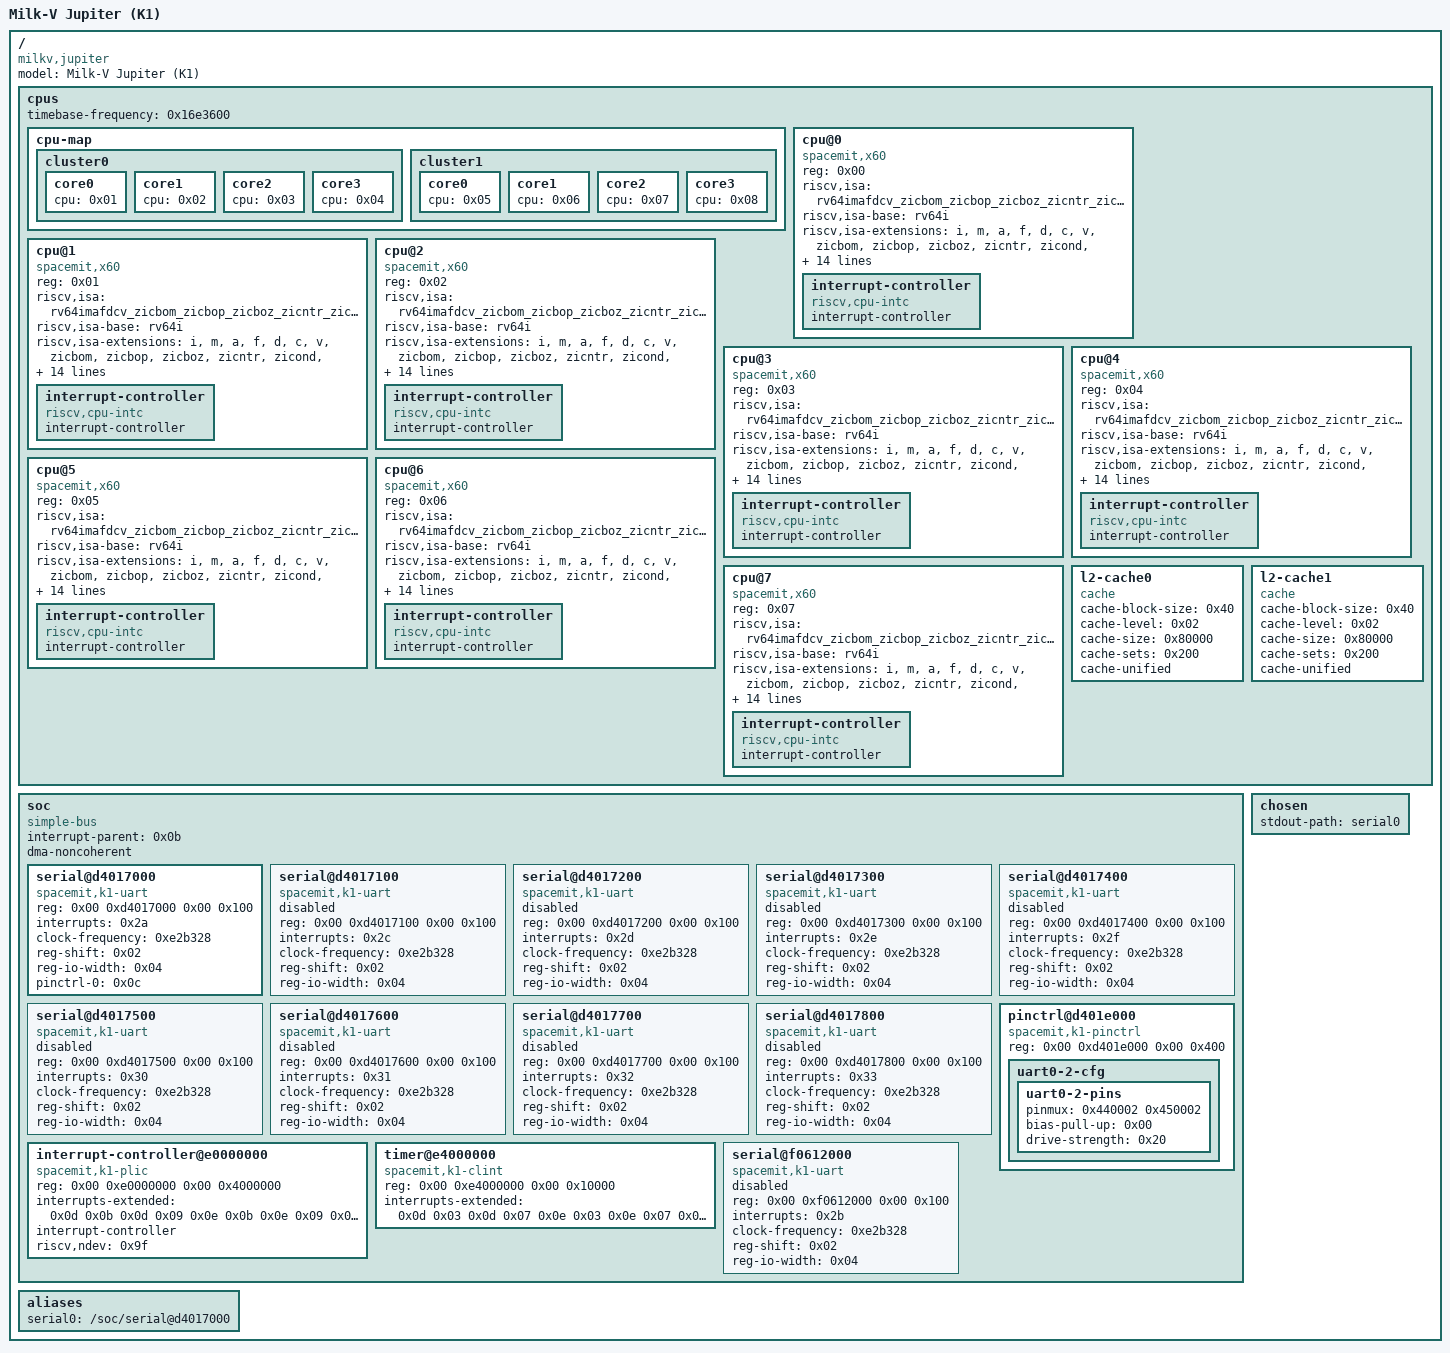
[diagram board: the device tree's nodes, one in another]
/dts-v1/;

/ {
	#address-cells = <0x02>;
	#size-cells = <0x02>;
	model = "Milk-V Jupiter (K1)";
	compatible = "milkv,jupiter", "spacemit,k1";

	cpus {
		#address-cells = <0x01>;
		#size-cells = <0x00>;
		timebase-frequency = <0x16e3600>;

		cpu-map {

			cluster0 {

				core0 {
					cpu = <0x01>;
				};

				core1 {
					cpu = <0x02>;
				};

				core2 {
					cpu = <0x03>;
				};

				core3 {
					cpu = <0x04>;
				};
			};

			cluster1 {

				core0 {
					cpu = <0x05>;
				};

				core1 {
					cpu = <0x06>;
				};

				core2 {
					cpu = <0x07>;
				};

				core3 {
					cpu = <0x08>;
				};
			};
		};

		cpu@0 {
			compatible = "spacemit,x60", "riscv";
			device_type = "cpu";
			reg = <0x00>;
			riscv,isa = "rv64imafdcv_zicbom_zicbop_zicboz_zicntr_zicond_zicsr_zifencei_zihintpause_zihpm_zfh_zba_zbb_zbc_zbs_zkt_zvfh_zvkt_sscofpmf_sstc_svinval_svnapot_svpbmt";
			riscv,isa-base = "rv64i";
			riscv,isa-extensions = "i", "m", "a", "f", "d", "c", "v", "zicbom", "zicbop", "zicboz", "zicntr", "zicond", "zicsr", "zifencei", "zihintpause", "zihpm", "zfh", "zba", "zbb", "zbc", "zbs", "zkt", "zvfh", "zvkt", "sscofpmf", "sstc", "svinval", "svnapot", "svpbmt";
			riscv,cbom-block-size = <0x40>;
			riscv,cbop-block-size = <0x40>;
			riscv,cboz-block-size = <0x40>;
			i-cache-block-size = <0x40>;
			i-cache-size = <0x8000>;
			i-cache-sets = <0x80>;
			d-cache-block-size = <0x40>;
			d-cache-size = <0x8000>;
			d-cache-sets = <0x80>;
			next-level-cache = <0x09>;
			mmu-type = "riscv,sv39";
			phandle = <0x01>;

			interrupt-controller {
				compatible = "riscv,cpu-intc";
				interrupt-controller;
				#interrupt-cells = <0x01>;
				phandle = <0x0d>;
			};
		};

		cpu@1 {
			compatible = "spacemit,x60", "riscv";
			device_type = "cpu";
			reg = <0x01>;
			riscv,isa = "rv64imafdcv_zicbom_zicbop_zicboz_zicntr_zicond_zicsr_zifencei_zihintpause_zihpm_zfh_zba_zbb_zbc_zbs_zkt_zvfh_zvkt_sscofpmf_sstc_svinval_svnapot_svpbmt";
			riscv,isa-base = "rv64i";
			riscv,isa-extensions = "i", "m", "a", "f", "d", "c", "v", "zicbom", "zicbop", "zicboz", "zicntr", "zicond", "zicsr", "zifencei", "zihintpause", "zihpm", "zfh", "zba", "zbb", "zbc", "zbs", "zkt", "zvfh", "zvkt", "sscofpmf", "sstc", "svinval", "svnapot", "svpbmt";
			riscv,cbom-block-size = <0x40>;
			riscv,cbop-block-size = <0x40>;
			riscv,cboz-block-size = <0x40>;
			i-cache-block-size = <0x40>;
			i-cache-size = <0x8000>;
			i-cache-sets = <0x80>;
			d-cache-block-size = <0x40>;
			d-cache-size = <0x8000>;
			d-cache-sets = <0x80>;
			next-level-cache = <0x09>;
			mmu-type = "riscv,sv39";
			phandle = <0x02>;

			interrupt-controller {
				compatible = "riscv,cpu-intc";
				interrupt-controller;
				#interrupt-cells = <0x01>;
				phandle = <0x0e>;
			};
		};

		cpu@2 {
			compatible = "spacemit,x60", "riscv";
			device_type = "cpu";
			reg = <0x02>;
			riscv,isa = "rv64imafdcv_zicbom_zicbop_zicboz_zicntr_zicond_zicsr_zifencei_zihintpause_zihpm_zfh_zba_zbb_zbc_zbs_zkt_zvfh_zvkt_sscofpmf_sstc_svinval_svnapot_svpbmt";
			riscv,isa-base = "rv64i";
			riscv,isa-extensions = "i", "m", "a", "f", "d", "c", "v", "zicbom", "zicbop", "zicboz", "zicntr", "zicond", "zicsr", "zifencei", "zihintpause", "zihpm", "zfh", "zba", "zbb", "zbc", "zbs", "zkt", "zvfh", "zvkt", "sscofpmf", "sstc", "svinval", "svnapot", "svpbmt";
			riscv,cbom-block-size = <0x40>;
			riscv,cbop-block-size = <0x40>;
			riscv,cboz-block-size = <0x40>;
			i-cache-block-size = <0x40>;
			i-cache-size = <0x8000>;
			i-cache-sets = <0x80>;
			d-cache-block-size = <0x40>;
			d-cache-size = <0x8000>;
			d-cache-sets = <0x80>;
			next-level-cache = <0x09>;
			mmu-type = "riscv,sv39";
			phandle = <0x03>;

			interrupt-controller {
				compatible = "riscv,cpu-intc";
				interrupt-controller;
				#interrupt-cells = <0x01>;
				phandle = <0x0f>;
			};
		};

		cpu@3 {
			compatible = "spacemit,x60", "riscv";
			device_type = "cpu";
			reg = <0x03>;
			riscv,isa = "rv64imafdcv_zicbom_zicbop_zicboz_zicntr_zicond_zicsr_zifencei_zihintpause_zihpm_zfh_zba_zbb_zbc_zbs_zkt_zvfh_zvkt_sscofpmf_sstc_svinval_svnapot_svpbmt";
			riscv,isa-base = "rv64i";
			riscv,isa-extensions = "i", "m", "a", "f", "d", "c", "v", "zicbom", "zicbop", "zicboz", "zicntr", "zicond", "zicsr", "zifencei", "zihintpause", "zihpm", "zfh", "zba", "zbb", "zbc", "zbs", "zkt", "zvfh", "zvkt", "sscofpmf", "sstc", "svinval", "svnapot", "svpbmt";
			riscv,cbom-block-size = <0x40>;
			riscv,cbop-block-size = <0x40>;
			riscv,cboz-block-size = <0x40>;
			i-cache-block-size = <0x40>;
			i-cache-size = <0x8000>;
			i-cache-sets = <0x80>;
			d-cache-block-size = <0x40>;
			d-cache-size = <0x8000>;
			d-cache-sets = <0x80>;
			next-level-cache = <0x09>;
			mmu-type = "riscv,sv39";
			phandle = <0x04>;

			interrupt-controller {
				compatible = "riscv,cpu-intc";
				interrupt-controller;
				#interrupt-cells = <0x01>;
				phandle = <0x10>;
			};
		};

		cpu@4 {
			compatible = "spacemit,x60", "riscv";
			device_type = "cpu";
			reg = <0x04>;
			riscv,isa = "rv64imafdcv_zicbom_zicbop_zicboz_zicntr_zicond_zicsr_zifencei_zihintpause_zihpm_zfh_zba_zbb_zbc_zbs_zkt_zvfh_zvkt_sscofpmf_sstc_svinval_svnapot_svpbmt";
			riscv,isa-base = "rv64i";
			riscv,isa-extensions = "i", "m", "a", "f", "d", "c", "v", "zicbom", "zicbop", "zicboz", "zicntr", "zicond", "zicsr", "zifencei", "zihintpause", "zihpm", "zfh", "zba", "zbb", "zbc", "zbs", "zkt", "zvfh", "zvkt", "sscofpmf", "sstc", "svinval", "svnapot", "svpbmt";
			riscv,cbom-block-size = <0x40>;
			riscv,cbop-block-size = <0x40>;
			riscv,cboz-block-size = <0x40>;
			i-cache-block-size = <0x40>;
			i-cache-size = <0x8000>;
			i-cache-sets = <0x80>;
			d-cache-block-size = <0x40>;
			d-cache-size = <0x8000>;
			d-cache-sets = <0x80>;
			next-level-cache = <0x0a>;
			mmu-type = "riscv,sv39";
			phandle = <0x05>;

			interrupt-controller {
				compatible = "riscv,cpu-intc";
				interrupt-controller;
				#interrupt-cells = <0x01>;
				phandle = <0x11>;
			};
		};

		cpu@5 {
			compatible = "spacemit,x60", "riscv";
			device_type = "cpu";
			reg = <0x05>;
			riscv,isa = "rv64imafdcv_zicbom_zicbop_zicboz_zicntr_zicond_zicsr_zifencei_zihintpause_zihpm_zfh_zba_zbb_zbc_zbs_zkt_zvfh_zvkt_sscofpmf_sstc_svinval_svnapot_svpbmt";
			riscv,isa-base = "rv64i";
			riscv,isa-extensions = "i", "m", "a", "f", "d", "c", "v", "zicbom", "zicbop", "zicboz", "zicntr", "zicond", "zicsr", "zifencei", "zihintpause", "zihpm", "zfh", "zba", "zbb", "zbc", "zbs", "zkt", "zvfh", "zvkt", "sscofpmf", "sstc", "svinval", "svnapot", "svpbmt";
			riscv,cbom-block-size = <0x40>;
			riscv,cbop-block-size = <0x40>;
			riscv,cboz-block-size = <0x40>;
			i-cache-block-size = <0x40>;
			i-cache-size = <0x8000>;
			i-cache-sets = <0x80>;
			d-cache-block-size = <0x40>;
			d-cache-size = <0x8000>;
			d-cache-sets = <0x80>;
			next-level-cache = <0x0a>;
			mmu-type = "riscv,sv39";
			phandle = <0x06>;

			interrupt-controller {
				compatible = "riscv,cpu-intc";
				interrupt-controller;
				#interrupt-cells = <0x01>;
				phandle = <0x12>;
			};
		};

		cpu@6 {
			compatible = "spacemit,x60", "riscv";
			device_type = "cpu";
			reg = <0x06>;
			riscv,isa = "rv64imafdcv_zicbom_zicbop_zicboz_zicntr_zicond_zicsr_zifencei_zihintpause_zihpm_zfh_zba_zbb_zbc_zbs_zkt_zvfh_zvkt_sscofpmf_sstc_svinval_svnapot_svpbmt";
			riscv,isa-base = "rv64i";
			riscv,isa-extensions = "i", "m", "a", "f", "d", "c", "v", "zicbom", "zicbop", "zicboz", "zicntr", "zicond", "zicsr", "zifencei", "zihintpause", "zihpm", "zfh", "zba", "zbb", "zbc", "zbs", "zkt", "zvfh", "zvkt", "sscofpmf", "sstc", "svinval", "svnapot", "svpbmt";
			riscv,cbom-block-size = <0x40>;
			riscv,cbop-block-size = <0x40>;
			riscv,cboz-block-size = <0x40>;
			i-cache-block-size = <0x40>;
			i-cache-size = <0x8000>;
			i-cache-sets = <0x80>;
			d-cache-block-size = <0x40>;
			d-cache-size = <0x8000>;
			d-cache-sets = <0x80>;
			next-level-cache = <0x0a>;
			mmu-type = "riscv,sv39";
			phandle = <0x07>;

			interrupt-controller {
				compatible = "riscv,cpu-intc";
				interrupt-controller;
				#interrupt-cells = <0x01>;
				phandle = <0x13>;
			};
		};

		cpu@7 {
			compatible = "spacemit,x60", "riscv";
			device_type = "cpu";
			reg = <0x07>;
			riscv,isa = "rv64imafdcv_zicbom_zicbop_zicboz_zicntr_zicond_zicsr_zifencei_zihintpause_zihpm_zfh_zba_zbb_zbc_zbs_zkt_zvfh_zvkt_sscofpmf_sstc_svinval_svnapot_svpbmt";
			riscv,isa-base = "rv64i";
			riscv,isa-extensions = "i", "m", "a", "f", "d", "c", "v", "zicbom", "zicbop", "zicboz", "zicntr", "zicond", "zicsr", "zifencei", "zihintpause", "zihpm", "zfh", "zba", "zbb", "zbc", "zbs", "zkt", "zvfh", "zvkt", "sscofpmf", "sstc", "svinval", "svnapot", "svpbmt";
			riscv,cbom-block-size = <0x40>;
			riscv,cbop-block-size = <0x40>;
			riscv,cboz-block-size = <0x40>;
			i-cache-block-size = <0x40>;
			i-cache-size = <0x8000>;
			i-cache-sets = <0x80>;
			d-cache-block-size = <0x40>;
			d-cache-size = <0x8000>;
			d-cache-sets = <0x80>;
			next-level-cache = <0x0a>;
			mmu-type = "riscv,sv39";
			phandle = <0x08>;

			interrupt-controller {
				compatible = "riscv,cpu-intc";
				interrupt-controller;
				#interrupt-cells = <0x01>;
				phandle = <0x14>;
			};
		};

		l2-cache0 {
			compatible = "cache";
			cache-block-size = <0x40>;
			cache-level = <0x02>;
			cache-size = <0x80000>;
			cache-sets = <0x200>;
			cache-unified;
			phandle = <0x09>;
		};

		l2-cache1 {
			compatible = "cache";
			cache-block-size = <0x40>;
			cache-level = <0x02>;
			cache-size = <0x80000>;
			cache-sets = <0x200>;
			cache-unified;
			phandle = <0x0a>;
		};
	};

	soc {
		compatible = "simple-bus";
		interrupt-parent = <0x0b>;
		#address-cells = <0x02>;
		#size-cells = <0x02>;
		dma-noncoherent;
		ranges;

		serial@d4017000 {
			compatible = "spacemit,k1-uart", "intel,xscale-uart";
			reg = <0x00 0xd4017000 0x00 0x100>;
			interrupts = <0x2a>;
			clock-frequency = <0xe2b328>;
			reg-shift = <0x02>;
			reg-io-width = <0x04>;
			status = "okay";
			pinctrl-names = "default";
			pinctrl-0 = <0x0c>;
		};

		serial@d4017100 {
			compatible = "spacemit,k1-uart", "intel,xscale-uart";
			reg = <0x00 0xd4017100 0x00 0x100>;
			interrupts = <0x2c>;
			clock-frequency = <0xe2b328>;
			reg-shift = <0x02>;
			reg-io-width = <0x04>;
			status = "disabled";
		};

		serial@d4017200 {
			compatible = "spacemit,k1-uart", "intel,xscale-uart";
			reg = <0x00 0xd4017200 0x00 0x100>;
			interrupts = <0x2d>;
			clock-frequency = <0xe2b328>;
			reg-shift = <0x02>;
			reg-io-width = <0x04>;
			status = "disabled";
		};

		serial@d4017300 {
			compatible = "spacemit,k1-uart", "intel,xscale-uart";
			reg = <0x00 0xd4017300 0x00 0x100>;
			interrupts = <0x2e>;
			clock-frequency = <0xe2b328>;
			reg-shift = <0x02>;
			reg-io-width = <0x04>;
			status = "disabled";
		};

		serial@d4017400 {
			compatible = "spacemit,k1-uart", "intel,xscale-uart";
			reg = <0x00 0xd4017400 0x00 0x100>;
			interrupts = <0x2f>;
			clock-frequency = <0xe2b328>;
			reg-shift = <0x02>;
			reg-io-width = <0x04>;
			status = "disabled";
		};

		serial@d4017500 {
			compatible = "spacemit,k1-uart", "intel,xscale-uart";
			reg = <0x00 0xd4017500 0x00 0x100>;
			interrupts = <0x30>;
			clock-frequency = <0xe2b328>;
			reg-shift = <0x02>;
			reg-io-width = <0x04>;
			status = "disabled";
		};

		serial@d4017600 {
			compatible = "spacemit,k1-uart", "intel,xscale-uart";
			reg = <0x00 0xd4017600 0x00 0x100>;
			interrupts = <0x31>;
			clock-frequency = <0xe2b328>;
			reg-shift = <0x02>;
			reg-io-width = <0x04>;
			status = "disabled";
		};

		serial@d4017700 {
			compatible = "spacemit,k1-uart", "intel,xscale-uart";
			reg = <0x00 0xd4017700 0x00 0x100>;
			interrupts = <0x32>;
			clock-frequency = <0xe2b328>;
			reg-shift = <0x02>;
			reg-io-width = <0x04>;
			status = "disabled";
		};

		serial@d4017800 {
			compatible = "spacemit,k1-uart", "intel,xscale-uart";
			reg = <0x00 0xd4017800 0x00 0x100>;
			interrupts = <0x33>;
			clock-frequency = <0xe2b328>;
			reg-shift = <0x02>;
			reg-io-width = <0x04>;
			status = "disabled";
		};

		pinctrl@d401e000 {
			compatible = "spacemit,k1-pinctrl";
			reg = <0x00 0xd401e000 0x00 0x400>;

			uart0-2-cfg {
				phandle = <0x0c>;

				uart0-2-pins {
					pinmux = <0x440002 0x450002>;
					bias-pull-up = <0x00>;
					drive-strength = <0x20>;
				};
			};
		};

		interrupt-controller@e0000000 {
			compatible = "spacemit,k1-plic", "sifive,plic-1.0.0";
			reg = <0x00 0xe0000000 0x00 0x4000000>;
			interrupts-extended = <0x0d 0x0b 0x0d 0x09 0x0e 0x0b 0x0e 0x09 0x0f 0x0b 0x0f 0x09 0x10 0x0b 0x10 0x09 0x11 0x0b 0x11 0x09 0x12 0x0b 0x12 0x09 0x13 0x0b 0x13 0x09 0x14 0x0b 0x14 0x09>;
			interrupt-controller;
			#address-cells = <0x00>;
			#interrupt-cells = <0x01>;
			riscv,ndev = <0x9f>;
			phandle = <0x0b>;
		};

		timer@e4000000 {
			compatible = "spacemit,k1-clint", "sifive,clint0";
			reg = <0x00 0xe4000000 0x00 0x10000>;
			interrupts-extended = <0x0d 0x03 0x0d 0x07 0x0e 0x03 0x0e 0x07 0x0f 0x03 0x0f 0x07 0x10 0x03 0x10 0x07 0x11 0x03 0x11 0x07 0x12 0x03 0x12 0x07 0x13 0x03 0x13 0x07 0x14 0x03 0x14 0x07>;
		};

		serial@f0612000 {
			compatible = "spacemit,k1-uart", "intel,xscale-uart";
			reg = <0x00 0xf0612000 0x00 0x100>;
			interrupts = <0x2b>;
			clock-frequency = <0xe2b328>;
			reg-shift = <0x02>;
			reg-io-width = <0x04>;
			status = "reserved";
		};
	};

	aliases {
		serial0 = "/soc/serial@d4017000";
	};

	chosen {
		stdout-path = "serial0";
	};
};
